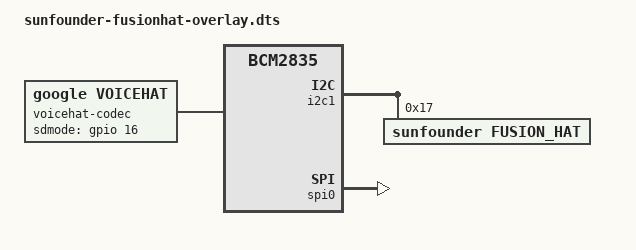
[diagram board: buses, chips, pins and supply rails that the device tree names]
/dts-v1/;
/plugin/;

/ {
	compatible = "brcm,bcm2835";

    fragment@0 {
        target = <&i2c1>;
        __overlay__ {
            #address-cells = <1>;
            #size-cells = <0>;

            fusion_hat: fusion_hat@17 {
                compatible = "sunfounder,fusion_hat";
                reg = <0x17>;
                status = "okay";
            };
        };
    };
	fragment@1 {
		target-path = "/chosen";
		__overlay__ {
			power: power {
				hat_current_supply = <5000>;
			};
		};
	};
	fragment@2 {
		target = <&i2c1>;
		__overlay__ {
			status = "okay";
		};
	};
	fragment@3 {
		target = <&spi0>;
		__overlay__ {
			status = "okay";
		};
	};

    	fragment@4 {
		target = <&i2s_clk_producer>;
		__overlay__ {
			status = "okay";
		};
    	};
	fragment@5 {
		target = <&gpio>;
		__overlay__ {
			googlevoicehat_pins: googlevoicehat_pins {
				brcm,pins = <16>;
				brcm,function = <1>; /* out */
				brcm,pull = <0>; /* up */
			};
		};
	};
	fragment@6 {
		target-path = "/";
		__overlay__ {
			voicehat-codec {
				#sound-dai-cells = <0>;
				compatible = "google,voicehat";
				pinctrl-names = "default";
				pinctrl-0 = <&googlevoicehat_pins>;
				sdmode-gpios= <&gpio 16 0>;
				status = "okay";
			};
		};
	};
	fragment@7 {
		target = <&sound>;
		__overlay__ {
			compatible = "googlevoicehat,googlevoicehat-soundcard";
			i2s-controller = <&i2s_clk_producer>;
			status = "okay";
		};
	};
};
